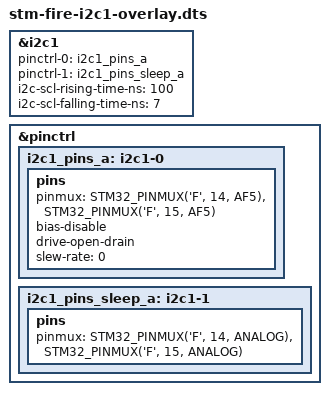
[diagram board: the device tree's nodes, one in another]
// SPDX-License-Identifier: (GPL-2.0+ OR BSD-3-Clause)
/*
 * Copyright (C) STMicroelectronics 2018 - All Rights Reserved
 * Author: Alexandre Torgue <alexandre.torgue@st.com>.
 */

/dts-v1/;
/plugin/;
//#include "../stm32mp157c.dtsi"
#include <dt-bindings/pinctrl/stm32-pinfunc.h>
#include <dt-bindings/input/input.h>
#include <dt-bindings/mfd/st,stpmic1.h>
#include <dt-bindings/gpio/gpio.h>

/{
	fragment@0{
		target=<&i2c1>;
		__overlay__{
			pinctrl-names = "default", "sleep";
			pinctrl-0 = <&i2c1_pins_a>;
			pinctrl-1 = <&i2c1_pins_sleep_a>;
			i2c-scl-rising-time-ns = <100>;
			i2c-scl-falling-time-ns = <7>;
			status = "okay";
			/delete-property/dmas;
			/delete-property/dma-names;		
		};
	};
	fragment@1{
		target=<&pinctrl>;
		__overlay__{
			i2c1_pins_a: i2c1-0 {
				pins {
					pinmux = <STM32_PINMUX('F', 14, AF5)>, /* I2C1_SCL */
						 <STM32_PINMUX('F', 15, AF5)>; /* I2C1_SDA */
					bias-disable;
					drive-open-drain;
					slew-rate = <0>;
				};
			};

			i2c1_pins_sleep_a: i2c1-1 {
				pins {
					pinmux = <STM32_PINMUX('F', 14, ANALOG)>, /* I2C1_SCL */
						 <STM32_PINMUX('F', 15, ANALOG)>; /* I2C1_SDA */
				};
			};
		};
	};
};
